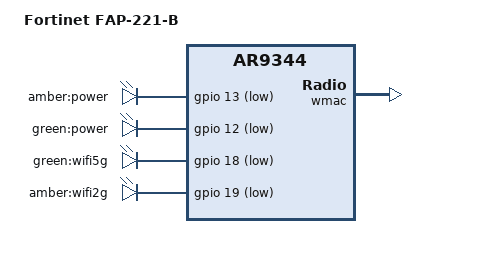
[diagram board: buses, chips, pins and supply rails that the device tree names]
// SPDX-License-Identifier: GPL-2.0-or-later OR MIT

#include "ar9344_fortinet_ap-dual.dtsi"

/ {
	model = "Fortinet FAP-221-B";
	compatible = "fortinet,fap-221-b", "qca,ar9344";

	leds {
		compatible = "gpio-leds";

		power_amber {
			label = "amber:power";
			gpios = <&gpio 13 GPIO_ACTIVE_LOW>;
			default-state = "off";
		};

		led_power: power_green {
			label = "green:power";
			gpios = <&gpio 12 GPIO_ACTIVE_LOW>;
			default-state = "on";
		};

		wifi5g {
			label = "green:wifi5g";
			gpios = <&gpio 18 GPIO_ACTIVE_LOW>;
			linux,default-trigger = "phy0tpt";
		};

		wifi2g {
			label = "amber:wifi2g";
			gpios = <&gpio 19 GPIO_ACTIVE_LOW>;
			linux,default-trigger = "phy1tpt";
		};
	};
};

&ath9k {
	ieee80211-freq-limit = <2402000 2482000>;
};

&wmac {
	ieee80211-freq-limit = <2402000 2482000 4900000 5990000>;

	mac-address-increment = <1>;
};

&art {
	compatible = "nvmem-cells";

	calibration_wmac: calibration@1000 {
		reg = <0x1000 0x440>;
	};

	calibration_pcie: calibration@5000 {
		reg = <0x5000 0x440>;
	};
};
